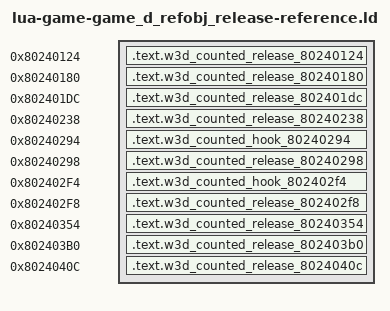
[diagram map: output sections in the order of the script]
/* Generated reference-only placements. All bodies are source-built. */
OUTPUT_FORMAT("elf32-powerpc")
OUTPUT_ARCH(powerpc)
ENTRY(w3d_counted_release_80240124)
_SDA_BASE_ = 0x804b2540;
_SDA2_BASE_ = 0x804c2540;
w3d_counted_destroy_8023c7d0 = 0x8023c7d0;
w3d_counted_destroy_8023c940 = 0x8023c940;
w3d_counted_destroy_8023cc94 = 0x8023cc94;
w3d_counted_destroy_8023d398 = 0x8023d398;
w3d_counted_destroy_8023d5b0 = 0x8023d5b0;
w3d_counted_destroy_8023d774 = 0x8023d774;
w3d_counted_destroy_8023da24 = 0x8023da24;
w3d_counted_destroy_8023dbe8 = 0x8023dbe8;
w3d_counted_destroy_8023def4 = 0x8023def4;
w3d_counted_unlink_8023c750 = 0x8023c750;
w3d_counted_unlink_8023c8b8 = 0x8023c8b8;
w3d_counted_unlink_8023ca64 = 0x8023ca64;
w3d_counted_unlink_8023d2e8 = 0x8023d2e8;
w3d_counted_unlink_8023d530 = 0x8023d530;
w3d_counted_unlink_8023d698 = 0x8023d698;
w3d_counted_unlink_8023d9a4 = 0x8023d9a4;
w3d_counted_unlink_8023db0c = 0x8023db0c;
w3d_counted_unlink_8023de18 = 0x8023de18;
SECTIONS {
  .text.w3d_counted_release_80240124 0x80240124 : { *(.text.w3d_counted_release_80240124) }
  .text.w3d_counted_release_80240180 0x80240180 : { *(.text.w3d_counted_release_80240180) }
  .text.w3d_counted_release_802401dc 0x802401dc : { *(.text.w3d_counted_release_802401dc) }
  .text.w3d_counted_release_80240238 0x80240238 : { *(.text.w3d_counted_release_80240238) }
  .text.w3d_counted_hook_80240294 0x80240294 : { *(.text.w3d_counted_hook_80240294) }
  .text.w3d_counted_release_80240298 0x80240298 : { *(.text.w3d_counted_release_80240298) }
  .text.w3d_counted_hook_802402f4 0x802402f4 : { *(.text.w3d_counted_hook_802402f4) }
  .text.w3d_counted_release_802402f8 0x802402f8 : { *(.text.w3d_counted_release_802402f8) }
  .text.w3d_counted_release_80240354 0x80240354 : { *(.text.w3d_counted_release_80240354) }
  .text.w3d_counted_release_802403b0 0x802403b0 : { *(.text.w3d_counted_release_802403b0) }
  .text.w3d_counted_release_8024040c 0x8024040c : { *(.text.w3d_counted_release_8024040c) }
  /DISCARD/ : { *(.text*) *(.rodata*) *(.data*) *(.bss*) *(.sdata*) *(.sbss*) *(.comment) }
}
